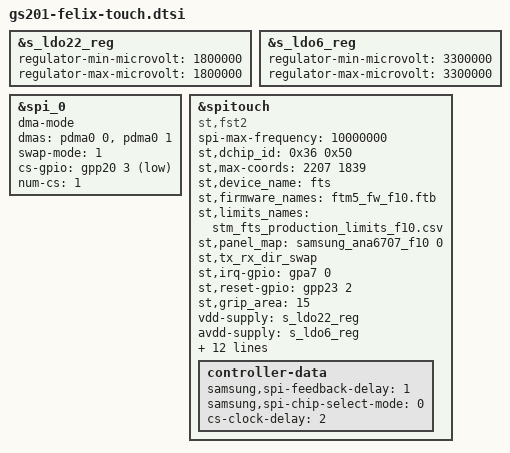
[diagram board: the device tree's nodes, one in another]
// SPDX-License-Identifier: GPL-2.0-only
/*
 * Google L10 touch device tree source
 *
 * Copyright 2022 Google Inc.
 *
 */

#include <arm64/exynos/exynos-pinctrl.h>

&s_ldo22_reg {
	regulator-min-microvolt = <1800000>;
	regulator-max-microvolt = <1800000>;
	/delete-property/ regulator-always-on;
};

&s_ldo6_reg {
	regulator-min-microvolt = <3300000>;
	regulator-max-microvolt = <3300000>;
	/delete-property/ regulator-always-on;
};

&spi_0 {
	status = "okay";
	dma-mode;
	dmas = <&pdma0 0 &pdma0 1>;
	swap-mode = <1> ;
	cs-gpio = <&gpp20 3 GPIO_ACTIVE_LOW>;
	num-cs = <1>;
};

&spitouch {
	status = "ok";
	compatible = "st,fst2";
	spi-max-frequency = <10000000>;
	st,dchip_id = /bits/ 8 <0x36 0x50>;
	st,max-coords = <2207 1839>;
	st,device_name = "fts";
	st,firmware_names = "ftm5_fw_f10.ftb";
	st,limits_names = "stm_fts_production_limits_f10.csv";
	st,panel_map = <&samsung_ana6707_f10 0>;
	st,tx_rx_dir_swap;
	pinctrl-names = "pmx_ts_active", "pmx_ts_suspend";
	st,irq-gpio = <&gpa7 0 0>;
	st,reset-gpio = <&gpp23 2 0>;
	/* Either st,panel_map or st,max-coords should be used
	 * in the product touch dtsi */
	st,grip_area = /bits/ 8 <15>; /* Left and right grip rejection
					 area. Unit: pixels */
	vdd-supply = <&s_ldo22_reg>; /* VIO 1.8V, different from common. */
	avdd-supply = <&s_ldo6_reg>; /* AVDD 3.3V, different from common. */
	st,mm2px = /bits/ 8 <15>; /* 2208 px / 150 mm  = 14.7 */
	goog,dev-id = <0>;
	goog,tbn-enabled;
	goog,offload-enabled;
	goog,v4l2-enabled;
	goog,touch_offload_id = /bits/ 8 <'f''1''0''0'>; /* outer: 1; inner 0 */
	goog,display-resolution = /bits/ 16 <2208 1840>;
	goog,channel-num = /bits/ 16 <39 32>;
	goog,offload-caps-data-types = /bits/ 16 <0x1f>;
	goog,offload-caps-scan-types = /bits/ 16 <0xc0>;
	goog,default-grip-disabled;
	goog,default-palm-disabled;

	controller-data {
		samsung,spi-feedback-delay = <1>;
		samsung,spi-chip-select-mode = <0>;
		cs-clock-delay = <2>;
	};
};
